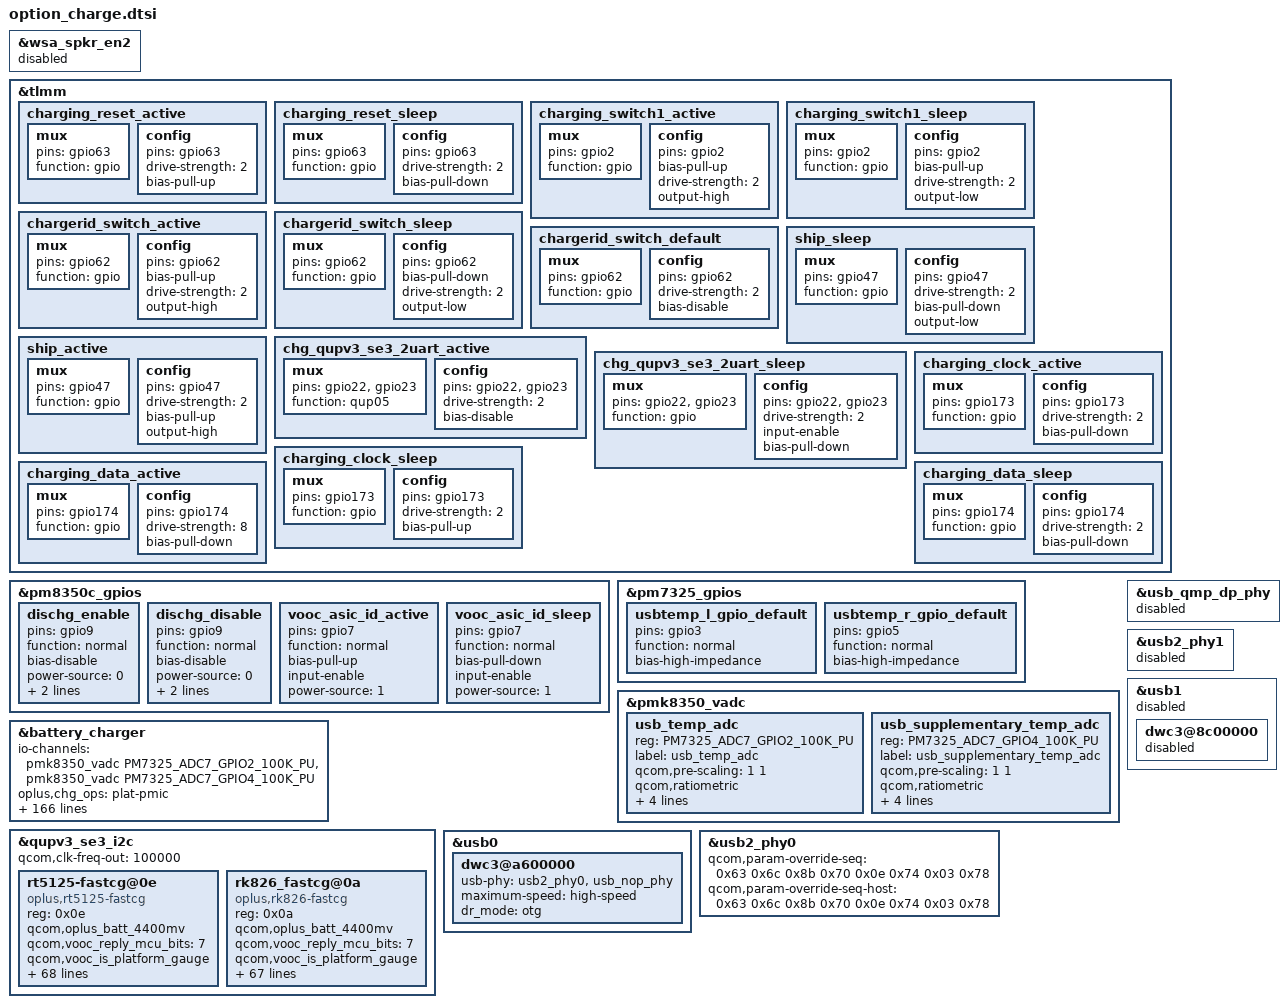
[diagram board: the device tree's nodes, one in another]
#include "oplus_vadc.h"

/*&qupv3_se6_i2c {
	status = "disabled";
};

&tx_swr_gpios {
	status = "disabled";
};

&qupv3_se15_spi {
	status = "disabled";
};

*/
&wsa_spkr_en2 {
	status = "disabled";
};
/*for gpio24: qupv3_se6_i2c, for gpio2: tx_swr_gpios, for gpio62: qupv3_se15_spi, for gpio62: wsa_spkr_en2*/

&tlmm {
	charging_reset_active: charging_reset_active {
		mux {
			pins = "gpio63";
			function = "gpio";
		};

		config {
			pins = "gpio63";
			drive-strength = <2>;
			bias-pull-up;
		};
	};

	charging_reset_sleep: charging_reset_sleep {
		mux {
			pins = "gpio63";
			function = "gpio";
		};

		config {
			pins = "gpio63";
			drive-strength = <2>;
			bias-pull-down;
		};
	};
	charging_switch1_active: charging_switch1_active {
		mux {
			pins = "gpio2";
			function = "gpio";
		};
		config {
			pins = "gpio2";
			bias-pull-up;
			drive-strength = <2>;
			output-high;
		};
	};

	charging_switch1_sleep: charging_switch1_sleep {
		mux {
			pins = "gpio2";
			function = "gpio";
		};
		config {
			pins = "gpio2";
			bias-pull-up;
			drive-strength = <2>;
			output-low;
		};
	};
	
	chargerid_switch_active: chargerid_switch_active {
		mux {
			pins = "gpio62";
			function = "gpio";
		};
		config {
			pins = "gpio62";
			bias-pull-up;
			drive-strength = <2>;
			output-high;
		};
	};

	chargerid_switch_sleep: chargerid_switch_sleep {
		mux {
			pins = "gpio62";
			function = "gpio";
		};
		config {
			pins = "gpio62";
			bias-pull-down;
			drive-strength = <2>;
			output-low;
		};
	};

	chargerid_switch_default: chargerid_switch_default {
		mux {
			pins = "gpio62";
			function = "gpio";
		};

		config {
			pins = "gpio62";
			drive-strength = <2>;
			bias-disable; /* NO PULL */
		};
	};

	ship_sleep: ship_sleep {
		mux {
			pins = "gpio47";
			function = "gpio";
		};

		config {
			pins = "gpio47";
			drive-strength = <2>;
			bias-pull-down;
			output-low;
		};
	};

	ship_active: ship_active {
		mux {
			pins = "gpio47";
			function = "gpio";
		};

		config {
			pins = "gpio47";
			drive-strength = <2>;
			bias-pull-up;
			output-high;
		};
	};
	
	chg_qupv3_se3_2uart_active: chg_qupv3_se3_2uart_active {
		mux {
			pins = "gpio22", "gpio23";
			function = "qup05";
		};

		config {
			pins = "gpio22", "gpio23";
			drive-strength = <2>;
			bias-disable;
		};
	};

	chg_qupv3_se3_2uart_sleep: chg_qupv3_se3_2uart_sleep {
		mux {
			pins = "gpio22", "gpio23";
			function = "gpio";
		};

		config {
			pins = "gpio22", "gpio23";
			drive-strength = <2>;
			input-enable;
			bias-pull-down;
		};
	};
	charging_clock_active: charging_clock_active {
		mux {
			pins = "gpio173";
			function = "gpio";
		};

		config {
			pins = "gpio173";
			drive-strength = <2>;
			bias-pull-down;
		};
	};

	charging_clock_sleep: charging_clock_sleep {
		mux {
			pins = "gpio173";
			function = "gpio";
		};

		config {
			pins = "gpio173";
			drive-strength = <2>;
			bias-pull-up;
		};
	};

	charging_data_active: charging_data_active {
		mux {
			pins = "gpio174";
			function = "gpio";
		};

		config {
			pins = "gpio174";
			drive-strength = <8>;
			bias-pull-down;
		};
	};

	charging_data_sleep: charging_data_sleep {
		mux {
			pins = "gpio174";
			function = "gpio";
		};

		config {
			pins = "gpio174";
			drive-strength = <2>;
			bias-pull-down;
		};
	};
};

&pm8350c_gpios {
	dischg_enable: dischg_enable {
		pins = "gpio9";
		function = "normal";
		bias-disable;
		power-source = <0>;
		output-high;
		qcom,drive-strength = <3>;
	};

	dischg_disable: dischg_disable {
		pins = "gpio9";
		function = "normal";
		bias-disable;
		power-source = <0>;
		output-low;
		qcom,drive-strength = <3>;
	};

	vooc_asic_id_active: vooc_asic_id_active {
		pins = "gpio7";
		function = "normal";
		bias-pull-up;
		input-enable;
		power-source = <1>;
	};

	vooc_asic_id_sleep: vooc_asic_id_sleep {
		pins = "gpio7";
		function = "normal";
		bias-pull-down;
		input-enable;
		power-source = <1>;
	};
};

&pm7325_gpios {
	usbtemp_l_gpio_default: usbtemp_l_gpio_default {
		pins = "gpio3";
		function = "normal";
		bias-high-impedance;
	};
	usbtemp_r_gpio_default: usbtemp_r_gpio_default {
		pins = "gpio5";
		function = "normal";
		bias-high-impedance;
	};
};

&pmk8350_vadc {
	usb_temp_adc {
		reg = <PM7325_ADC7_GPIO2_100K_PU>;
		label = "usb_temp_adc";
		qcom,pre-scaling = <1 1>;
		qcom,ratiometric;
		qcom,hw-settle-time = <200>;
		oplus,cust_type = <IIO_VOLTAGE>;
		oplus,cust_scale_fn_type = <SCALE_HW_CALIB_DEFAULT>;
	};
	usb_supplementary_temp_adc {
		reg = <PM7325_ADC7_GPIO4_100K_PU>;
		label = "usb_supplementary_temp_adc";
		qcom,pre-scaling = <1 1>;
		qcom,ratiometric;
		qcom,hw-settle-time = <200>;
		oplus,cust_type = <IIO_VOLTAGE>;
		oplus,cust_scale_fn_type = <SCALE_HW_CALIB_DEFAULT>;
	};
};

&battery_charger {
	io-channels	= <&pmk8350_vadc PM7325_ADC7_GPIO2_100K_PU>,
					<&pmk8350_vadc PM7325_ADC7_GPIO4_100K_PU>;
	io-channel-names = "usb_temp_adc",
						"usb_supplementary_temp_adc";
};

&battery_charger {
	//for oplus chg framework:
	oplus,chg_ops = "plat-pmic";
	qcom,smart_charging_screenoff;
	qcom,input_current_charger_ma = <2000>;
	qcom,pd_input_current_charger_ma = <3000>;
	qcom,qc_input_current_charger_ma = <2000>;
	qcom,input_current_usb_ma = <500>;
	qcom,input_current_cdp_ma = <1500>;
	qcom,input_current_led_ma = <1200>;
	qcom,input_current_led_ma_high = <1800>;
	qcom,input_current_led_ma_warm = <1800>;
	qcom,input_current_led_ma_normal = <2000>;
	qcom,led_warm_bat_decidegc = <350>;
	qcom,led_high_bat_decidegc = <370>;
	qcom,input_current_camera_ma = <1200>;
	qcom,input_current_vooc_led_ma_high = <1800>;
	qcom,input_current_vooc_led_ma_warm = <1800>;
	qcom,input_current_vooc_led_ma_normal = <3600>;
	qcom,input_current_vooc_ma_normal = <3600>;
	qcom,vooc_temp_bat_normal_decidegc = <350>;
	qcom,input_current_vooc_ma_warm = <3200>;
	qcom,vooc_temp_bat_warm_decidegc = <370>;
	qcom,input_current_vooc_ma_high = <2200>;
	qcom,vooc_temp_bat_hot_decidegc = <440>;
	qcom,charger_current_vooc_ma_normal = <1800>;

	qcom,chg_ctrl_by_calling;
	qcom,input_current_calling_ma = <1500>;

	//qcom,input_current_led_ma_overtemp = <900>;
	qcom,overtemp_bat_decidegc = <350>;
	qcom,iterm_disabled = <0>;
	qcom,iterm_ma = <254>;
	qcom,recharge-mv = <100>;
	qcom,batt_capacity_mah = <5000>;/*typical capacity*/
	//qcom,batt_capacity_mah = <4880>; /*rated capacity*/

	qcom,removed_bat_decidegc = <190>;  /*<-19C*/

	qcom,cold_bat_decidegc = <20>;  /*-2C~0C*/
	qcom,temp_cold_vfloat_mv = <3980>;
	qcom,temp_cold_fastchg_current_ma = <300>;

	qcom,little_cold_bat_decidegc = <0>;	/*0C~5C*/
	qcom,temp_little_cold_vfloat_mv = <4435>;
	qcom,temp_little_cold_fastchg_current_ma_high = <2200>;
	qcom,temp_little_cold_fastchg_current_ma_low = <2200>;
	qcom,temp_little_cold_fastchg_current_ma = <2200>;
	qcom,pd_temp_little_cold_fastchg_current_ma_high = <3000>;
	qcom,pd_temp_little_cold_fastchg_current_ma_low = <2300>;
	qcom,qc_temp_little_cold_fastchg_current_ma_high = <2000>;
	qcom,qc_temp_little_cold_fastchg_current_ma_low = <1450>;

	qcom,cool_bat_decidegc = <50>;	/*5C~12C*/
	qcom,temp_cool_vfloat_mv = <4435>;
	qcom,temp_cool_fastchg_current_ma_high = <2200>;
	qcom,temp_cool_fastchg_current_ma_low = <2200>;
	qcom,pd_temp_cool_fastchg_current_ma_high = <3300>;
	qcom,pd_temp_cool_fastchg_current_ma_low = <3000>;
	qcom,qc_temp_cool_fastchg_current_ma_high = <2000>;
	qcom,qc_temp_cool_fastchg_current_ma_low = <2000>;

	qcom,little_cool_bat_decidegc = <120>;	/*12C~16C*/
	qcom,temp_little_cool_vfloat_mv = <4435>;
	qcom,temp_little_cool_fastchg_current_ma = <2200>;
	qcom,pd_temp_little_cool_fastchg_current_ma = <3300>;
	qcom,qc_temp_little_cool_fastchg_current_ma = <2000>;

	qcom,normal_bat_decidegc = <160>;	/*16C~44C*/
	qcom,temp_normal_fastchg_current_ma = <2200>;
	qcom,temp_normal_vfloat_mv = <4435>;
	qcom,pd_temp_normal_fastchg_current_ma = <3300>;
	qcom,qc_temp_normal_fastchg_current_ma = <2000>;

	qcom,warm_bat_decidegc = <450>;		/*45C~53C*/ /*8pin Bat Vooc project need add 3 degree C*/
	qcom,temp_warm_vfloat_mv = <4130>;
	qcom,temp_warm_fastchg_current_ma = <1350>;
	qcom,pd_temp_warm_fastchg_current_ma = <1350>;
	qcom,qc_temp_warm_fastchg_current_ma = <600>;
	qcom,temp_warm_fastchg_current_ma_led_on = <550>;

	qcom,hot_bat_decidegc = <530>;

	qcom,non_standard_vfloat_mv = <3980>;
	qcom,non_standard_fastchg_current_ma = <512>;

	qcom,short_c_bat_cv_mv = <4330>;
	qcom,short_c_bat_vfloat_mv = <3800>;
	qcom,short_c_bat_fastchg_current_ma = <512>;

	qcom,cold_vfloat_sw_limit = <3930>;
	qcom,little_cold_vfloat_sw_limit = <4385>;
	qcom,cool_vfloat_sw_limit = <4385>;
	qcom,little_cool_vfloat_sw_limit = <4385>;
	qcom,normal_vfloat_sw_limit = <4385>;
	qcom,warm_vfloat_sw_limit = <4080>;
	qcom,non_standard_vfloat_sw_limit = <3930>;
	qcom,short_c_bat_vfloat_sw_limit = <3750>;

	qcom,max_chg_time_sec = <70272>;
	qcom,charger_hv_thr = <5800>;
	qcom,charger_recv_thr = <5500>;
	qcom,charger_lv_thr = <3400>;
	qcom,vbatt_full_thr = <4435>;
	qcom,vbatt_hv_thr = <4600>;
	qcom,vfloat_step_mv = <8>;
	qcom,non_standard_vfloat_over_sw_limit = <3990>;
	qcom,cold_vfloat_over_sw_limit = <3990>;
	qcom,little_cold_vfloat_over_sw_limit = <4445>;
	qcom,cool_vfloat_over_sw_limit = <4445>;
	qcom,little_cool_vfloat_over_sw_limit = <4445>;
	qcom,normal_vfloat_over_sw_limit = <4445>;
	qcom,warm_vfloat_over_sw_limit = <4140>;

	qcom,vbatt_power_off = <3300>;
	qcom,vbatt_soc_1 = <3310>;
	qcom,vooc_project = <1>;//5v6A
	//qcom,vbatt_num = <2>;
	qcom,internal_gauge_with_asic = <1>;
	qcom,ffc_support;
	qcom,dual_ffc;
	//recharge_after_full;
	//qcom,wireless_support;
	//qcom,wpc_no_chargerpump;
	qcom,fg_info_package_read_support;
	qcom,normal_vterm_hw_inc = <18>;
	qcom,non_normal_vterm_hw_inc = <18>;

	qcom,ff1_normal_fastchg_ma = <1500>;
	qcom,ff1_warm_fastchg_ma = <1500>;
	qcom,ffc2_normal_fastchg_ma = <1300>;/*12C~35c*/
	qcom,ffc2_temp_warm_decidegc = <350>;
	qcom,ffc2_warm_fastchg_ma = <1400>;/*35C~40c*/
	qcom,ffc2_temp_high_decidegc = <400>;
	qcom,ffc2_temp_low_decidegc = <120>;
	qcom,ffc2_exit_step_ma = <200>;
	qcom,ff1_exit_step_ma = <400>;
	qcom,ff1_warm_exit_step_ma = <300>;

	qcom,ffc_normal_vfloat_sw_limit = <4475>;
	qcom,ffc2_normal_vfloat_sw_limit = <4475>;
	qcom,ffc2_warm_vfloat_sw_limit = <4475>;
	qcom,ffc_temp_normal_vfloat_mv = <4550>;
	qcom,ffc1_temp_normal_vfloat_mv = <4550>;
	qcom,ffc2_temp_normal_vfloat_mv = <4550>;
	qcom,ffc_normal_vfloat_over_sw_limit = <4550>;
	qcom,ffc1_normal_vfloat_over_sw_limit = <4550>;
	qcom,ffc2_normal_vfloat_over_sw_limit = <4550>;

	qcom,default_iterm_ma = <254>;
	qcom,default_temp_normal_fastchg_current_ma = <2200>;
	qcom,default_normal_vfloat_sw_limit = <4385>;
	qcom,default_temp_normal_vfloat_mv = <4435>;
	qcom,default_normal_vfloat_over_sw_limit = <4445>;

	qcom,default_temp_little_cool_fastchg_current_ma = <2200>;
	qcom,default_little_cool_vfloat_sw_limit = <4385>;
	qcom,default_temp_little_cool_vfloat_mv = <4435>;
	qcom,default_little_cool_vfloat_over_sw_limit = <4445>;

	///qcom,offset_temp = <30>;
	//for control:
	//qcom,suspend_after_full;
	qcom,check_batt_full_by_sw;
	//qcom,external_gauge;
	qcom,chg_ctrl_by_lcd;
	//qcom,chg_ctrl_by_vooc;
	qcom,chg_ctrl_by_camera;
	qcom,sw_vfloat_over_protect_enable;
	qcom,usbtemp_batttemp_gap = <10>;
	//qcom,voocphy_support;
        qcom,fg_in_adsp_support;
	qcom,chargerid_switch-gpio = <&tlmm 62 0x00>;
	//for PD9V or QC9V
	//qcom,vbatt_pdqc_to_5v_thr = <4100>;
	qcom,vbatt_pdqc_to_9v_thr = <5000>;/*always 9v*/
	qcom,vooc_show_ui_soc_decimal;
	qcom,ui_soc_decimal_speedmin = <20>;//2A
	qcom,otg_scheme = <2>;//0:cid 1:ccdetect_gpio 2:switch

	qcom,dischg-gpio = <&pm8350c_gpios 9 0x00>;
	pinctrl-names = "dischg_enable", "dischg_disable",
			"chargerid_switch_active", "chargerid_switch_sleep", "chargerid_switch_default",
			"chg_qupv3_se3_2uart_active", "chg_qupv3_se3_2uart_sleep",
			"usbtemp_l_gpio_default", "usbtemp_r_gpio_default";

	pinctrl-0 = <&dischg_enable>;
	pinctrl-1 = <&dischg_disable>;
	pinctrl-2 = <&chargerid_switch_active>;
	pinctrl-3 = <&chargerid_switch_sleep>;
	pinctrl-4 = <&chargerid_switch_default>;
	pinctrl-5 = <&chg_qupv3_se3_2uart_active>;
	pinctrl-6 = <&chg_qupv3_se3_2uart_sleep>;
	pinctrl-7 = <&usbtemp_l_gpio_default>;
	pinctrl-8 = <&usbtemp_r_gpio_default>;
};

&qupv3_se3_i2c {
      status = "ok";
      qcom,clk-freq-out = <100000>;

	  rt5125-fastcg@0e {
		status = "ok";
		compatible = "oplus,rt5125-fastcg";
		reg = <0x0e>;

		qcom,oplus_batt_4400mv;
		//qcom,vooc_fw_update_newmethod;
		qcom,vooc_reply_mcu_bits = <7>;
		qcom,vooc_is_platform_gauge;
		qcom,vooc-low-temp = <0>;
		qcom,vooc-high-temp = <430>;
		qcom,vooc-low-soc = <1>;
		qcom,vooc-high-soc = <90>;
		qcom,vooc-little-cold-temp = <50>;
		qcom,vooc-cool-temp = <120>;
		qcom,vooc-little-cool-temp = <160>;
		qcom,vooc-normal-low-temp = <250>;
		qcom,vooc-little-cool-to-normal-temp = <180>;
		qcom,vooc-fw-type = <11>;//30W

		qcom,vooc_cool_bat_volt = <3650>;
		qcom,vooc_little_cool_bat_volt = <3550>;
		qcom,vooc_normal_bat_volt = <3450>;
		qcom,vooc_warm_bat_volt = <3350>;

		qcom,vooc_cool_bat_suspend_volt = <3650>;
		qcom,vooc_little_cool_bat_suspend_volt = <3550>;
		qcom,vooc_normal_bat_suspend_volt = <3450>;
		qcom,vooc_warm_bat_suspend_volt = <3350>;

		qcom,vooc_multistep_adjust_current_support;
		qcom,vooc_multistep_initial_batt_temp = <1000>;
		qcom,vooc_strategy_normal_current = <0x0b>;

		qcom,vooc-normal-to-little-cool-current = <0x05>;
		qcom,vooc_batt_over_high_temp = <440>;
		qcom,vooc_batt_over_low_temp = <45>;
		qcom,vooc_over_high_or_low_current = <0x0>;

		qcom,vooc_strategy1_batt_high_temp0 = <410>;
		qcom,vooc_strategy1_batt_high_temp1 = <425>;
		qcom,vooc_strategy1_batt_high_temp2 = <435>;
		qcom,vooc_strategy1_batt_low_temp2 = <430>;
		qcom,vooc_strategy1_batt_low_temp1 = <410>;
		qcom,vooc_strategy1_batt_low_temp0 = <390>;

		qcom,vooc_strategy1_high_current0 = <0x07>;//4A
		qcom,vooc_strategy1_high_current1 = <0x05>;//3A
		qcom,vooc_strategy1_high_current2 = <0x04>;//2A
		qcom,vooc_strategy1_low_current2 = <0x05>;//3A
		qcom,vooc_strategy1_low_current1 = <0x09>;//5A
		qcom,vooc_strategy1_low_current0 = <0x0b>;//6A


		qcom,vooc_strategy2_batt_up_temp1 = <370>;
		qcom,vooc_strategy2_batt_up_down_temp2 = <380>;
		qcom,vooc_strategy2_batt_up_temp3 = <390>;
		qcom,vooc_strategy2_batt_up_down_temp4 = <395>;
		qcom,vooc_strategy2_batt_up_temp5 = <400>;
		qcom,vooc_strategy2_batt_up_temp6 = <415>;
		qcom,vooc_strategy2_high0_current = <0x06>;
		qcom,vooc_strategy2_high1_current = <0x06>;
		qcom,vooc_strategy2_high2_current = <0x06>;
		qcom,vooc_strategy2_high3_current = <0x06>;

		
		qcom,vooc_current_lvl = <1000
								1500
								2000
								2500
								3000
								3500
								4000
								4500
								5000
								5500
								6000
								6500
								7000
								7500
								8000
								8500
								9000
								9500
								10000
								10500
								11000
								11500
								12000
								12500>;

		pinctrl-names = "switch1_act_switch2_act", "switch1_sleep_switch2_sleep",
						"switch1_act_switch3_act", "switch1_sleep_switch3_sleep",
						"switch1_act_switch2_sleep", "switch1_sleep_switch2_act",
						"clock_active","clock_sleep",
						"data_active","data_sleep",
						"reset_active","reset_sleep",
						"vooc_asic_id_active","vooc_asic_id_sleep";
		pinctrl-0 = <&charging_switch1_active>;
		pinctrl-1 = <&charging_switch1_sleep>;
		pinctrl-2 = <&charging_switch1_active>;
		pinctrl-3 = <&charging_switch1_sleep>;
		pinctrl-4 = <&charging_switch1_active>;
		pinctrl-5 = <&charging_switch1_sleep>;
		pinctrl-6 = <&charging_clock_active>;
		pinctrl-7 = <&charging_clock_sleep>;
		pinctrl-8 = <&charging_data_active>;
		pinctrl-9 = <&charging_data_sleep>;
		pinctrl-10 = <&charging_reset_active>;
		pinctrl-11 = <&charging_reset_sleep>;
		pinctrl-12 = <&vooc_asic_id_active>;
		pinctrl-13 = <&vooc_asic_id_sleep>;
		
		qcom,charging_switch1-gpio 		= <&tlmm 2 0x00>;

		qcom,charging_reset-gpio = <&tlmm 63 0x00>;
		qcom,charging_clock-gpio = <&tlmm 173 0x00>;
		qcom,charging_data-gpio = <&tlmm 174 0x00>;
		qcom,vooc_asic_id-gpio = <&pm8350c_gpios 7 0x00>;
	};

	rk826_fastcg@0a {
		status = "okay";
		compatible = "oplus,rk826-fastcg";
		reg = <0x0a>;
		qcom,oplus_batt_4400mv;
		//qcom,vooc_fw_update_newmethod;
		qcom,vooc_reply_mcu_bits = <7>;
		qcom,vooc_is_platform_gauge;
		qcom,vooc-low-temp = <0>;
		qcom,vooc-high-temp = <430>;
		qcom,vooc-low-soc = <1>;
		qcom,vooc-high-soc = <90>;
		qcom,vooc-little-cold-temp = <50>;
		qcom,vooc-cool-temp = <120>;
		qcom,vooc-little-cool-temp = <160>;
		qcom,vooc-normal-low-temp = <250>;
		qcom,vooc-little-cool-to-normal-temp = <180>;
		qcom,vooc-normal-to-little-cool-current = <0x05>;//5A
		qcom,vooc-fw-type = <9>;//30W

		qcom,vooc_cool_bat_volt = <3450>;
		qcom,vooc_little_cool_bat_volt = <3400>;
		qcom,vooc_normal_bat_volt = <3350>;
		qcom,vooc_warm_bat_volt = <3300>;

		qcom,vooc_cool_bat_suspend_volt = <3450>;
		qcom,vooc_little_cool_bat_suspend_volt = <3400>;
		qcom,vooc_normal_bat_suspend_volt = <3350>;
		qcom,vooc_warm_bat_suspend_volt = <3300>;

		qcom,vooc_multistep_adjust_current_support;
		qcom,vooc_multistep_initial_batt_temp = <1000>;
		qcom,vooc_strategy_normal_current = <0x0C>;

		qcom,vooc_batt_over_high_temp = <440>;
		qcom,vooc_over_high_or_low_current = <0x0>;

		qcom,vooc_strategy1_batt_high_temp0 = <425>;
		qcom,vooc_strategy1_batt_high_temp1 = <430>;
		qcom,vooc_strategy1_batt_high_temp2 = <435>;
		qcom,vooc_strategy1_batt_low_temp2 = <420>;
		qcom,vooc_strategy1_batt_low_temp1 = <415>;
		qcom,vooc_strategy1_batt_low_temp0 = <400>;

		qcom,vooc_strategy1_high_current0 = <0x09>;//4A
		qcom,vooc_strategy1_high_current1 = <0x07>;//3A
		qcom,vooc_strategy1_high_current2 = <0x05>;//2A
		qcom,vooc_strategy1_low_current2 = <0x07>;//3A
		qcom,vooc_strategy1_low_current1 = <0x09>;//4A
		qcom,vooc_strategy1_low_current0 = <0x0C>;//4A

		qcom,vooc_strategy2_batt_up_temp1 = <375>;
		qcom,vooc_strategy2_batt_up_down_temp2 = <380>;
		qcom,vooc_strategy2_batt_up_temp3 = <390>;
		qcom,vooc_strategy2_batt_up_down_temp4 = <400>;
		qcom,vooc_strategy2_batt_up_temp5 = <410>;
		qcom,vooc_strategy2_batt_up_temp6 = <415>;
		qcom,vooc_strategy2_high0_current = <0x05>;
		qcom,vooc_strategy2_high1_current = <0x04>;
		qcom,vooc_strategy2_high2_current = <0x03>;
		qcom,vooc_strategy2_high3_current = <0x02>;
		qcom,vooc_current_lvl = <1000
									1500
									2000
									2500
									3000
									3500
									4000
									4500
									5000
									5500
									6000
									6500
									7000
									7500
									8000
									8500
									9000
									9500
									10000
									10500
									11000
									11500
									12000
									12500>;

		pinctrl-names = "switch1_act_switch2_act", "switch1_sleep_switch2_sleep",
			"switch1_act_switch3_act", "switch1_sleep_switch3_sleep",
			"switch1_act_switch2_sleep", "switch1_sleep_switch2_act",
			"clock_active","clock_sleep",
			"data_active","data_sleep",
			"reset_active","reset_sleep",
			//"charging_switch1_ctr1_active","charging_switch1_ctr1_sleep",
			"vooc_asic_id_active","vooc_asic_id_sleep";

		pinctrl-0 = <&charging_switch1_active>;
		pinctrl-1 = <&charging_switch1_sleep >;
		pinctrl-2 = <&charging_switch1_active>;
		pinctrl-3 = <&charging_switch1_sleep >;
		pinctrl-4 = <&charging_switch1_active>;
		pinctrl-5 = <&charging_switch1_sleep>;
		pinctrl-6 = <&charging_clock_active >;
		pinctrl-7 = <&charging_clock_sleep >;
		pinctrl-8 = <&charging_data_active >;
		pinctrl-9 = <&charging_data_sleep >;
		pinctrl-10 = <&charging_reset_active >;
		pinctrl-11 = <&charging_reset_sleep >;
	//	pinctrl-12 = <&charging_switch1_ctr1_active >;
	//	pinctrl-13 = <&charging_switch1_ctr1_sleep >;
		pinctrl-12 = <&vooc_asic_id_active>;
		pinctrl-13 = <&vooc_asic_id_sleep>;

		qcom,charging_switch1-gpio = <&tlmm 2 0x00>;
	//	qcom,charging_switch1_ctr1-gpio = <&tlmm 71 0x00>;
		qcom,charging_reset-gpio = <&tlmm 63 0x00>;
		qcom,charging_clock-gpio = <&tlmm 173 0x00>;
		qcom,charging_data-gpio = <&tlmm 174 0x00>;
		qcom,vooc_asic_id-gpio = <&pm8350c_gpios 7 0x00>;
	};
};

&usb_qmp_dp_phy {
	status = "disabled";
};

&usb2_phy1 {
	status = "disabled";
};

&usb0 {
	/delete-property/ extcon;
	dwc3@a600000 {
		usb-phy = <&usb2_phy0>, <&usb_nop_phy>;
		maximum-speed = "high-speed";
		dr_mode = "otg";
	};
};

&usb1 {
	status = "disabled";
	dwc3@8c00000 {
		status = "disabled";
	};
};

&usb2_phy0 {
	qcom,param-override-seq =
			<0x63 0x6c
			 0x8b 0x70
			 0x0e 0x74
			 0x03 0x78>;

	qcom,param-override-seq-host =
			<0x63 0x6c
			 0x8b 0x70
			 0x0e 0x74
			 0x03 0x78>;
};

/*&pm7325b_gpios {
	cp_therm_gpio_default: cp_therm_gpio_default {
		pins = "gpio4";
		function = "normal";
		bias-high-impedance;
    };
	bat_therm_a_board_gpio_default: bat_therm_a_board_gpio_default {
		pins = "gpio3";
		function = "normal";
		bias-high-impedance;
    };
};

&pm7325_gpios {
	pa_4g_gpio_default: pa_4g_gpio_default {
		pins = "gpio1";
		function = "normal";
		bias-high-impedance;
    };
	pa_5g_gpio_default: pa_5g_gpio_default {
        pins = "gpio4";
		function = "normal";
        bias-high-impedance;
    };
};

&pmk8350_vadc {
	pinctrl-names = "default";
	pinctrl-0 = <&pa_4g_gpio_default &pa_5g_gpio_default &cp_therm_gpio_default &bat_therm_a_board_gpio_default>;

	pa_4g_adc {
		reg = <PM7325_ADC7_AMUX_THM5_100K_PU>;
		label = "pa_4g_adc";
		qcom,pre-scaling = <1 1>;
		qcom,ratiometric;
		qcom,hw-settle-time = <200>;
		oplus,cust_type = <IIO_TEMP>;
		oplus,cust_scale_fn_type = <SCALE_HW_CALIB_THERM_100K_PULLUP>;
	};
	pa_5g_adc {
		reg = <PM7325_ADC7_GPIO3_100K_PU>;
		label = "pa_5g_adc";
		qcom,pre-scaling = <1 1>;
		qcom,ratiometric;
		qcom,hw-settle-time = <200>;
		oplus,cust_type = <IIO_TEMP>;
		oplus,cust_scale_fn_type = <SCALE_HW_CALIB_THERM_100K_PULLUP>;
	};
	cp_therm_adc {
		reg = <PM7325B_ADC7_GPIO4_100K_PU>;
		label = "cp_therm_adc";
		qcom,pre-scaling = <1 1>;
		qcom,ratiometric;
		qcom,hw-settle-time = <200>;
		oplus,cust_type = <IIO_TEMP>;
		oplus,cust_scale_fn_type = <SCALE_HW_CALIB_THERM_100K_PULLUP>;
	};
	bat_therm_a_board_adc {
		reg = <PM7325B_ADC7_GPIO3_100K_PU>;
		label = "bat_therm_a_board_adc";
		qcom,pre-scaling = <1 1>;
		qcom,ratiometric;
		qcom,hw-settle-time = <200>;
		oplus,cust_type = <IIO_TEMP>;
		oplus,cust_scale_fn_type = <SCALE_HW_CALIB_THERM_100K_PULLUP>;
	};
};

&pmk8350_adc_tm {
        io-channels = <&pmk8350_vadc PM7325_ADC7_AMUX_THM1_100K_PU>,
                        <&pmk8350_vadc PM7325_ADC7_AMUX_THM2_100K_PU>,
                        <&pmk8350_vadc PM7325_ADC7_AMUX_THM3_100K_PU>,
                        <&pmk8350_vadc PM7325_ADC7_AMUX_THM4_100K_PU>,
                        <&pmk8350_vadc PMK8350_ADC7_AMUX_THM1_100K_PU>,
                        <&pmk8350_vadc PM7325_ADC7_AMUX_THM5_100K_PU>,
                        <&pmk8350_vadc PM7325_ADC7_GPIO3_100K_PU>,
                        <&pmk8350_vadc PM7325B_ADC7_GPIO4_100K_PU>,
                        <&pmk8350_vadc PM7325B_ADC7_GPIO3_100K_PU>;
                        
        pa_4g_therm {
                reg = <PM7325_ADC7_AMUX_THM5_100K_PU>;
                qcom,ratiometric;
                qcom,hw-settle-time = <200>;
        };

        pa_5g_therm {
                reg = <PM7325_ADC7_GPIO3_100K_PU>;
                qcom,ratiometric;
                qcom,hw-settle-time = <200>;
        };
        
        cp_ic_therm {
                reg = <PM7325B_ADC7_GPIO4_100K_PU>;
                qcom,ratiometric;
                qcom,hw-settle-time = <200>;
        };

        bat_temp_a_board_therm {
                reg = <PM7325B_ADC7_GPIO3_100K_PU>;
                qcom,ratiometric;
                qcom,hw-settle-time = <200>;
        };
};

&thermal_zones {
        pa_4g_therm-usr {
                polling-delay-passive = <0>;
                polling-delay = <0>;
                thermal-governor = "user_space";
                thermal-sensors = <&pmk8350_adc_tm PM7325_ADC7_AMUX_THM5_100K_PU>;
                wake-capable-sensor;
                trips {
                        active-config0 {
                                temperature = <125000>;
                                hysteresis = <1000>;
                                type = "passive";
                        };
                };
        };

        pa_5g_therm-usr {
                polling-delay-passive = <0>;
                polling-delay = <0>;
                thermal-governor = "user_space";
                thermal-sensors = <&pmk8350_adc_tm PM7325_ADC7_GPIO3_100K_PU>;
                wake-capable-sensor;
                trips {
                        active-config0 {
                                temperature = <125000>;
                                hysteresis = <1000>;
                                type = "passive";
                        };
                };
        };

        cp_ic_therm-usr {
                polling-delay-passive = <0>;
                polling-delay = <0>;
                thermal-governor = "user_space";
                thermal-sensors = <&pmk8350_adc_tm PM7325B_ADC7_GPIO4_100K_PU>;
                wake-capable-sensor;
                trips {
                        active-config0 {
                                temperature = <125000>;
                                hysteresis = <1000>;
                                type = "passive";
                        };
                };
        };

        bat_temp_a_board_therm-usr {
                polling-delay-passive = <0>;
                polling-delay = <0>;
                thermal-governor = "user_space";
                thermal-sensors = <&pmk8350_adc_tm PM7325B_ADC7_GPIO3_100K_PU>;
                wake-capable-sensor;
                trips {
                        active-config0 {
                                temperature = <125000>;
                                hysteresis = <1000>;
                                type = "passive";
                        };
                };
        };
};*/
